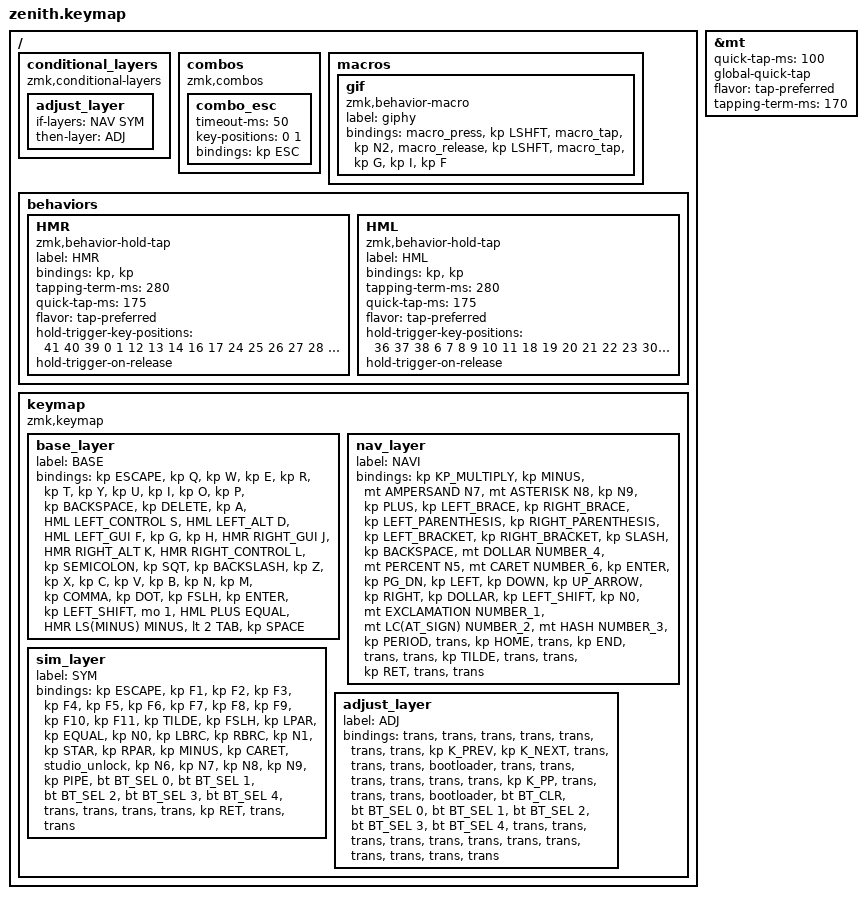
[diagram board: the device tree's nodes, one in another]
//
//                                                        ▀▀▀▀▀     ▀▀▀▀▀          ▀▀█▀▀
//                                                        ▄▀▀▀▄  ▄  ▄▀▀▀▄  ▄  ▄▀▀▀▄  █  ▄▀▀▀▄
//                                                        █   █  █  █   █  █  █   █  █  █   █
//                                                         ▀▀▀   █   ▀▀▀   █   ▀▀▀   ▀   ▀▀▀
//                                                               █      ▄▄▄█▄▄▄    █   █  
//                                                               ▀      █  █  █     █▄█
//                                                             ▀▀▀▀▀    █  █  █      ▀
//                                                                      ▀  ▀  ▀
//
// ▄▄▄▄▄▄▄▄▄▄▄▄▄▄▄▄▄▄▄▄▄▄▄▄▄▄▄▄▄▄▄▄▄▄▄▄▄▄▄▄▄▄▄▄▄▄▄▄▄▄▄▄▄▄▄▄▄▄▄▄▄▄▄▄▄▄▄▄▄▄▄▄▄▄▄▄▄▄▄▄▄▄▄▄▄▄▄▄▄▄▄▄▄▄▄▄▄▄▄▄▄▄▄▄▄▄▄▄▄▄▄▄▄▄▄▄▄▄▄▄▄▄▄▄▄▄▄▄▄▄▄▄▄▄▄▄▄▄▄▄▄▄▄▄▄▄▄▄▄

#include <behaviors.dtsi>
#include <dt-bindings/zmk/bt.h>
#include <dt-bindings/zmk/keys.h>

#define BASE 0
#define NAV  1
#define SYM  2
#define ADJ  3

&mt {
    quick-tap-ms = <100>;
    global-quick-tap;
    flavor = "tap-preferred";
    tapping-term-ms = <170>;
};

/ {
    conditional_layers {
        compatible = "zmk,conditional-layers";

        adjust_layer {
            if-layers = <NAV SYM>;
            then-layer = <ADJ>;
        };
    };

    combos {
        compatible = "zmk,combos";

        combo_esc {
            timeout-ms = <50>;
            key-positions = <0 1>;
            bindings = <&kp ESC>;
        };
    };

    macros {
        gif: gif {
            label = "giphy";
            compatible = "zmk,behavior-macro";
            #binding-cells = <0>;
            bindings =
                <&macro_press>,
                <&kp LSHFT>,
                <&macro_tap>,
                <&kp N2>,
                <&macro_release>,
                <&kp LSHFT>,
                <&macro_tap>,
                <&kp G &kp I &kp F>;
        };
    };

    behaviors {
        HMR: HMR {
            compatible = "zmk,behavior-hold-tap";
            label = "HMR";
            bindings = <&kp>, <&kp>;

            #binding-cells = <2>;
            tapping-term-ms = <280>;
            quick-tap-ms = <175>;
            flavor = "tap-preferred";
            hold-trigger-key-positions = <41 40 39 0 1 12 13 14 16 17 24 25 26 27 28 29 36 37 38 5 4 3 15 2>;
            hold-trigger-on-release;
        };

        HML: HML {
            compatible = "zmk,behavior-hold-tap";
            label = "HML";
            #binding-cells = <2>;
            bindings = <&kp>, <&kp>;

            tapping-term-ms = <280>;
            quick-tap-ms = <175>;
            flavor = "tap-preferred";
            hold-trigger-key-positions = <36 37 38 6 7 8 9 10 11 18 19 20 21 22 23 30 31 32 33 34 35 39 40 41>;
            hold-trigger-on-release;
        };
    };

    keymap {
        compatible = "zmk,keymap";

        // ▄▄▄▄▄▄▄▄▄▄▄▄▄▄▄▄▄▄▄▄▄▄▄▄▄▄▄▄▄▄▄▄▄▄▄▄▄▄▄▄▄▄▄▄▄▄▄▄▄▄▄▄▄▄▄▄▄▄▄▄▄▄▄▄▄▄▄▄▄▄▄▄▄▄▄▄▄▄▄▄▄▄▄▄▄▄▄▄▄▄▄▄▄▄▄▄▄▄▄▄▄▄▄▄▄▄▄▄▄▄▄▄▄▄▄▄▄▄▄▄▄▄▄▄▄▄▄▄▄▄▄▄▄▄▄▄▄▄▄▄▄▄▄▄▄▄▄▄▄

        base_layer {
            // ┏━━━━━━━━━━━━━━━━━━━━━━━━━━━━━━━━━━━━━━━┓

            label = "BASE";

            // ┗━━━━━━━━━━━━━━━━━━━━━━━━━━━━━━━━━━━━━━━┛

            bindings = <
&kp ESCAPE  &kp Q  &kp W  &kp E  &kp R  &kp T  &kp Y  &kp U  &kp I  &kp O  &kp P  &kp BACKSPACE  &kp DELETE  &kp A  &HML LEFT_CONTROL S  &HML LEFT_ALT D  &HML LEFT_GUI F  &kp G  &kp H  &HMR RIGHT_GUI J  &HMR RIGHT_ALT K  &HMR RIGHT_CONTROL L  &kp SEMICOLON  &kp SQT  &kp BACKSLASH  &kp Z  &kp X  &kp C  &kp V  &kp B  &kp N  &kp M  &kp COMMA  &kp DOT  &kp FSLH  &kp ENTER  &kp LEFT_SHIFT  &mo 1  &HML PLUS EQUAL  &HMR LS(MINUS) MINUS  &lt 2 TAB  &kp SPACE
            >;
        };

        // ▄▄▄▄▄▄▄▄▄▄▄▄▄▄▄▄▄▄▄▄▄▄▄▄▄▄▄▄▄▄▄▄▄▄▄▄▄▄▄▄▄▄▄▄▄▄▄▄▄▄▄▄▄▄▄▄▄▄▄▄▄▄▄▄▄▄▄▄▄▄▄▄▄▄▄▄▄▄▄▄▄▄▄▄▄▄▄▄▄▄▄▄▄▄▄▄▄▄▄▄▄▄▄▄▄▄▄▄▄▄▄▄▄▄▄▄▄▄▄▄▄▄▄▄▄▄▄▄▄▄▄▄▄▄▄▄▄▄▄▄▄▄▄▄▄▄▄▄▄

        nav_layer {
            // ┏━━━━━━━━━━━━━━━━━━━━━━━━━━━━━━━━━━━━━━━┓

            label = "NAVI";

            // ┗━━━━━━━━━━━━━━━━━━━━━━━━━━━━━━━━━━━━━━━┛

            bindings = <
&kp KP_MULTIPLY  &kp MINUS  &mt AMPERSAND N7  &mt ASTERISK N8  &kp N9  &kp PLUS  &kp LEFT_BRACE  &kp RIGHT_BRACE  &kp LEFT_PARENTHESIS  &kp RIGHT_PARENTHESIS  &kp LEFT_BRACKET  &kp RIGHT_BRACKET  &kp SLASH  &kp BACKSPACE  &mt DOLLAR NUMBER_4  &mt PERCENT N5  &mt CARET NUMBER_6  &kp ENTER  &kp PG_DN  &kp LEFT  &kp DOWN  &kp UP_ARROW  &kp RIGHT  &kp DOLLAR  &kp LEFT_SHIFT  &kp N0  &mt EXCLAMATION NUMBER_1  &mt LC(AT_SIGN) NUMBER_2  &mt HASH NUMBER_3  &kp PERIOD  &trans  &kp HOME  &trans  &kp END  &trans  &trans  &kp TILDE  &trans  &trans  &kp RET  &trans  &trans
            >;
        };

        // ▄▄▄▄▄▄▄▄▄▄▄▄▄▄▄▄▄▄▄▄▄▄▄▄▄▄▄▄▄▄▄▄▄▄▄▄▄▄▄▄▄▄▄▄▄▄▄▄▄▄▄▄▄▄▄▄▄▄▄▄▄▄▄▄▄▄▄▄▄▄▄▄▄▄▄▄▄▄▄▄▄▄▄▄▄▄▄▄▄▄▄▄▄▄▄▄▄▄▄▄▄▄▄▄▄▄▄▄▄▄▄▄▄▄▄▄▄▄▄▄▄▄▄▄▄▄▄▄▄▄▄▄▄▄▄▄▄▄▄▄▄▄▄▄▄▄▄▄▄

        sim_layer {
            // ┏━━━━━━━━━━━━━━━━━━━━━━━━━━━━━━━━━━━━━━━┓

            label = "SYM";

            // ┗━━━━━━━━━━━━━━━━━━━━━━━━━━━━━━━━━━━━━━━┛

            bindings = <
&kp ESCAPE  &kp F1  &kp F2  &kp F3  &kp F4  &kp F5  &kp F6  &kp F7  &kp F8  &kp F9  &kp F10  &kp F11  &kp TILDE  &kp FSLH  &kp LPAR  &kp EQUAL  &kp N0  &kp LBRC  &kp RBRC  &kp N1  &kp STAR  &kp RPAR  &kp MINUS  &kp CARET  &studio_unlock  &kp N6  &kp N7  &kp N8  &kp N9  &kp PIPE  &bt BT_SEL 0  &bt BT_SEL 1  &bt BT_SEL 2  &bt BT_SEL 3  &bt BT_SEL 4  &trans  &trans  &trans  &trans  &kp RET  &trans  &trans
            >;
        };

        // ▄▄▄▄▄▄▄▄▄▄▄▄▄▄▄▄▄▄▄▄▄▄▄▄▄▄▄▄▄▄▄▄▄▄▄▄▄▄▄▄▄▄▄▄▄▄▄▄▄▄▄▄▄▄▄▄▄▄▄▄▄▄▄▄▄▄▄▄▄▄▄▄▄▄▄▄▄▄▄▄▄▄▄▄▄▄▄▄▄▄▄▄▄▄▄▄▄▄▄▄▄▄▄▄▄▄▄▄▄▄▄▄▄▄▄▄▄▄▄▄▄▄▄▄▄▄▄▄▄▄▄▄▄▄▄▄▄▄▄▄▄▄▄▄▄▄▄▄▄

        adjust_layer {
            // ┏━━━━━━━━━━━━━━━━━━━━━━━━━━━━━━━━━━━━━━━┓

            label = "ADJ";

            // ┗━━━━━━━━━━━━━━━━━━━━━━━━━━━━━━━━━━━━━━━┛

            bindings = <
&trans  &trans  &trans  &trans  &trans  &trans  &trans  &kp K_PREV  &kp K_NEXT  &trans  &trans  &trans  &bootloader  &trans  &trans  &trans  &trans  &trans  &trans  &kp K_PP  &trans  &trans  &trans  &bootloader  &bt BT_CLR  &bt BT_SEL 0  &bt BT_SEL 1  &bt BT_SEL 2  &bt BT_SEL 3  &bt BT_SEL 4  &trans  &trans  &trans  &trans  &trans  &trans  &trans  &trans  &trans  &trans  &trans  &trans
            >;
        };
    };
};
